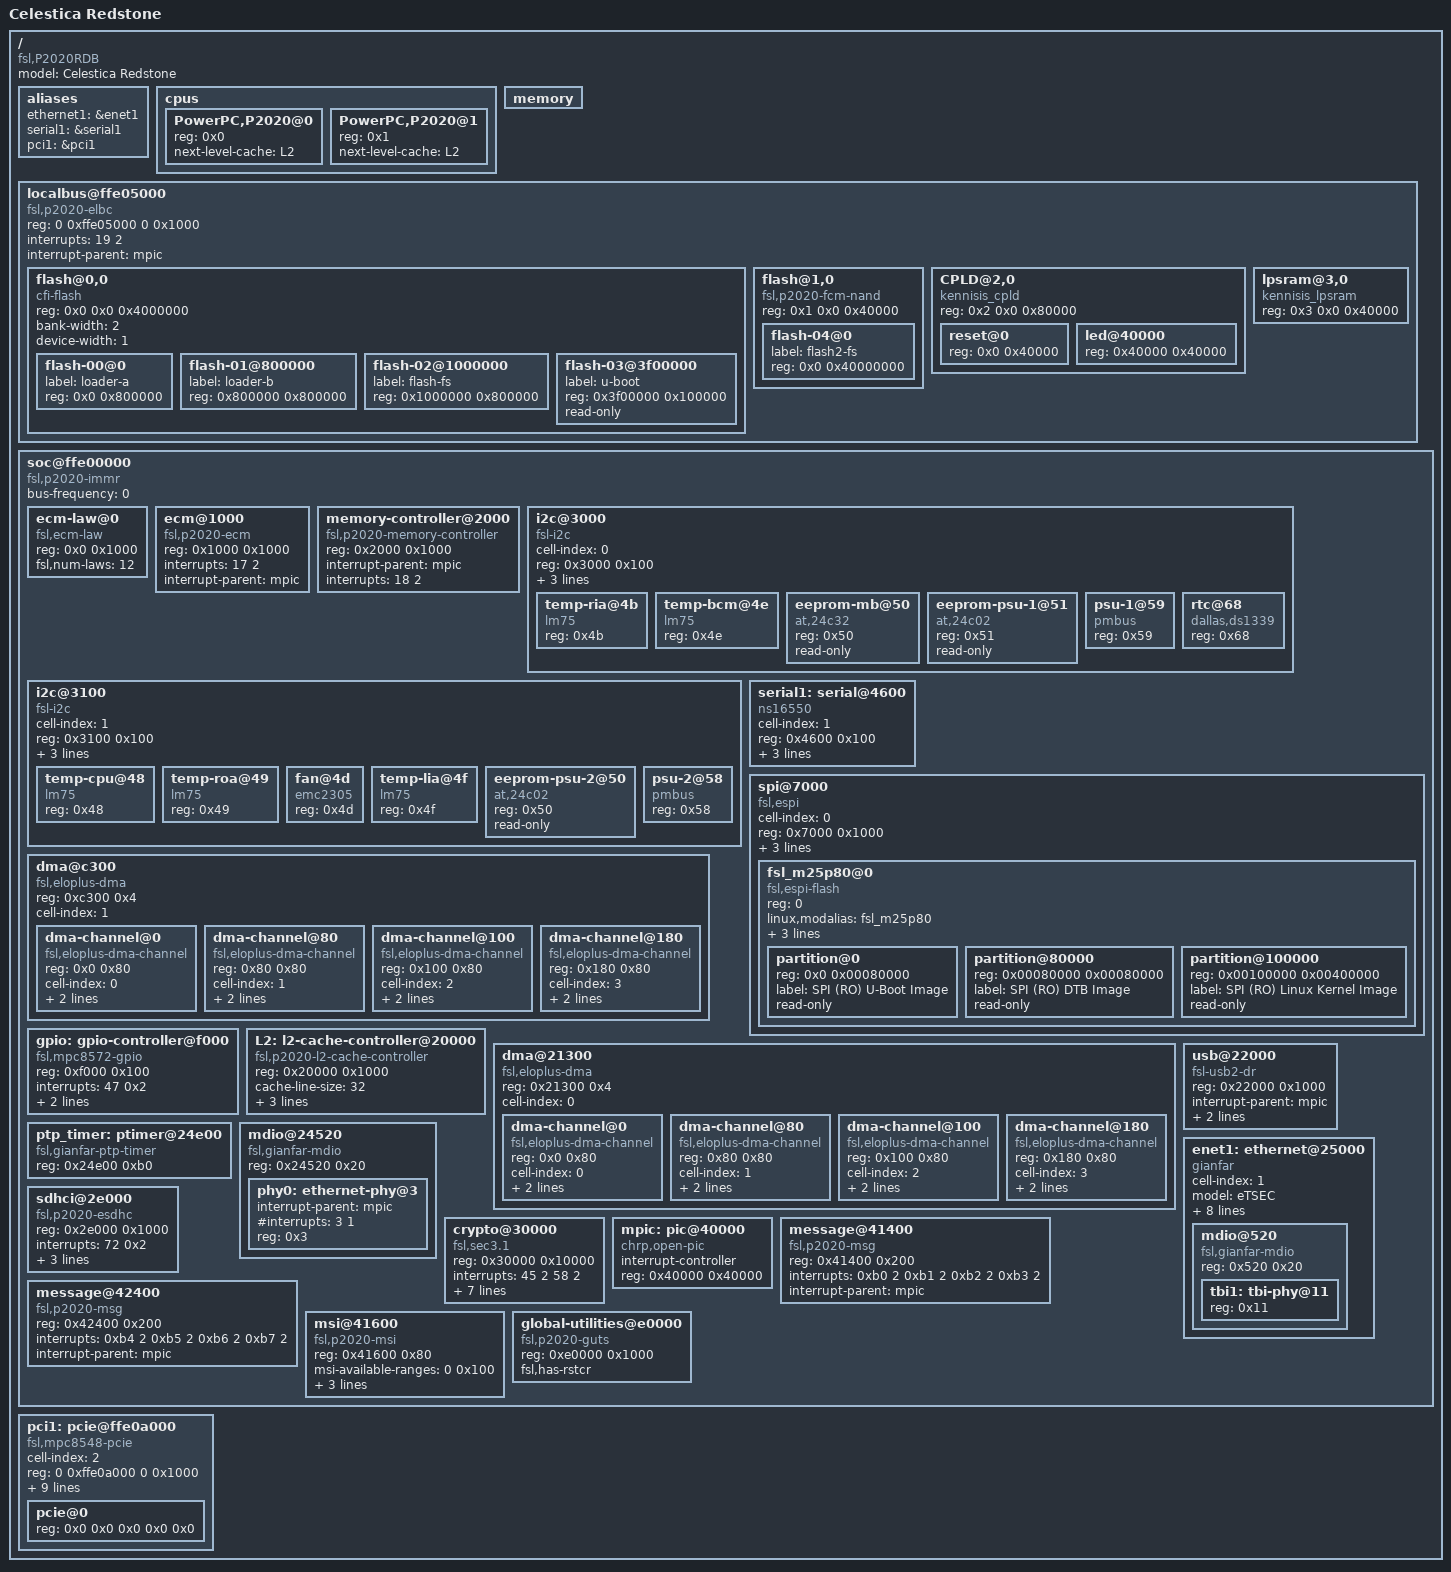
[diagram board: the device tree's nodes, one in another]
/*
 * Celestica Redstone device tree source
 *
 * Copyright 2013 Big Switch Networks, Inc.
 *
 * This program is free software; you can redistribute  it and/or modify it
 * under  the terms of  the GNU General  Public License as published by the
 * Free Software Foundation;  either version 2 of the  License, or (at your
 * option) any later version.
 */

/dts-v1/;

/ {
	model = "Celestica Redstone";
	compatible = "fsl,P2020RDB";
	#address-cells = <2>;
	#size-cells = <2>;

	aliases {
		ethernet1 = &enet1;
		serial1 = &serial1;
		pci1 = &pci1;
	};

	cpus {
		#address-cells = <1>;
		#size-cells = <0>;

		PowerPC,P2020@0 {
			device_type = "cpu";
			reg = <0x0>;
			next-level-cache = <&L2>;
		};

		PowerPC,P2020@1 {
			device_type = "cpu";
			reg = <0x1>;
			next-level-cache = <&L2>;
		};
	};

	memory {
		device_type = "memory";
	};

	localbus@ffe05000 {
		#address-cells = <2>;
		#size-cells = <1>;
		compatible = "fsl,p2020-elbc", "fsl,elbc", "simple-bus";
		reg = <0 0xffe05000 0 0x1000>;
		interrupts = <19 2>;
		interrupt-parent = <&mpic>;

		ranges = <0x0 0x0 0x0 0xec000000 0x4000000
			  0x1 0x0 0x0 0xffa00000 0x40000
			  0x2 0x0 0x0 0xffb00000 0x80000
			  0x3 0x0 0x0 0xffb80000 0x40000>;

		flash@0,0 {
			#address-cells = <1>;
			#size-cells = <1>;
			compatible = "cfi-flash";
			reg = <0x0 0x0 0x4000000>;
			bank-width = <2>;
			device-width = <1>;

			flash-00@0 {
				label = "loader-a";
				reg = <0x0 0x800000>;
			};

			flash-01@800000 {
				label = "loader-b";
				reg = <0x800000 0x800000>;
			};

			flash-02@1000000 {
				label = "flash-fs";
				reg = <0x1000000 0x800000>;
			};

			flash-03@3f00000 {
				label = "u-boot";
				reg = <0x3f00000 0x100000>;
				read-only;
			};
		};

		flash@1,0 {
			#address-cells = <1>;
			#size-cells = <1>;
			compatible = "fsl,p2020-fcm-nand",
				     "fsl,elbc-fcm-nand";
			reg = <0x1 0x0 0x40000>;

			flash-04@0 {
				label = "flash2-fs";
				reg = <0x0 0x40000000>;
			};
		};

		CPLD@2,0 {
			#address-cells = <1>;
			#size-cells = <1>;
			compatible = "kennisis_cpld";
			reg = <0x2 0x0 0x80000>;

			reset@0 {
				reg = <0x0 0x40000>;
			};
			led@40000 {
				reg = <0x40000 0x40000>;
			};
		};

		lpsram@3,0 {
			#address-cells = <1>;
			#size-cells = <1>;
			compatible = "kennisis_lpsram";
			reg = <0x3 0x0 0x40000>;
		};

	};

	soc@ffe00000 {
		#address-cells = <1>;
		#size-cells = <1>;
		device_type = "soc";
		compatible = "fsl,p2020-immr", "simple-bus";
		ranges = <0x0  0x0 0xffe00000 0x100000>;
		bus-frequency = <0>;		// Filled out by uboot.

		ecm-law@0 {
			compatible = "fsl,ecm-law";
			reg = <0x0 0x1000>;
			fsl,num-laws = <12>;
		};

		ecm@1000 {
			compatible = "fsl,p2020-ecm", "fsl,ecm";
			reg = <0x1000 0x1000>;
			interrupts = <17 2>;
			interrupt-parent = <&mpic>;
		};

		memory-controller@2000 {
			compatible = "fsl,p2020-memory-controller";
			reg = <0x2000 0x1000>;
			interrupt-parent = <&mpic>;
			interrupts = <18 2>;
		};

		i2c@3000 {
			#address-cells = <1>;
			#size-cells = <0>;
			cell-index = <0>;
			compatible = "fsl-i2c";
			reg = <0x3000 0x100>;
			interrupts = <43 2>;
			interrupt-parent = <&mpic>;
			dfsrr;

			temp-ria@4b {
				compatible = "lm75";
				reg = <0x4b>;
			};

			temp-bcm@4e {
				compatible = "lm75";
				reg = <0x4e>;
			};

			eeprom-mb@50 {
				compatible = "at,24c32";
				reg = <0x50>;
				read-only;
			};

			eeprom-psu-1@51 {
				compatible = "at,24c02";
				reg = <0x51>;
				read-only;
			};

			psu-1@59 {
				compatible = "pmbus";
				reg = <0x59>;
			};

			rtc@68 {
				compatible = "dallas,ds1339";
				reg = <0x68>;
			};

		};

		i2c@3100 {
			#address-cells = <1>;
			#size-cells = <0>;
			cell-index = <1>;
			compatible = "fsl-i2c";
			reg = <0x3100 0x100>;
			interrupts = <43 2>;
			interrupt-parent = <&mpic>;
			dfsrr;

			temp-cpu@48 {
				compatible = "lm75";
				reg = <0x48>;
			};

			temp-roa@49 {
				compatible = "lm75";
				reg = <0x49>;
			};

			fan@4d {
				compatible = "emc2305";
				reg = <0x4d>;
			};

			temp-lia@4f {
				compatible = "lm75";
				reg = <0x4f>;
			};

			eeprom-psu-2@50 {
				compatible = "at,24c02";
				reg = <0x50>;
				read-only;
			};

			psu-2@58 {
				compatible = "pmbus";
				reg = <0x58>;
			};
		};

		serial1: serial@4600 {
			cell-index = <1>;
			device_type = "serial";
			compatible = "ns16550";
			reg = <0x4600 0x100>;
			clock-frequency = <0>;
			interrupts = <42 2>;
			interrupt-parent = <&mpic>;
		};

		spi@7000 {
			cell-index = <0>;
			#address-cells = <1>;
			#size-cells = <0>;
			compatible = "fsl,espi";
			reg = <0x7000 0x1000>;
			interrupts = <59 0x2>;
			interrupt-parent = <&mpic>;
			mode = "cpu";

			fsl_m25p80@0 {
				#address-cells = <1>;
				#size-cells = <1>;
				compatible = "fsl,espi-flash";
				reg = <0>;
				linux,modalias = "fsl_m25p80";
				modal = "s25sl128b";
				spi-max-frequency = <32000000>;
				mode = <0>;

				partition@0 {
					/* 512KB for u-boot Bootloader Image */
					reg = <0x0 0x00080000>;
					label = "SPI (RO) U-Boot Image";
					read-only;
				};

				partition@80000 {
					/* 512KB for DTB Image */
					reg = <0x00080000 0x00080000>;
					label = "SPI (RO) DTB Image";
					read-only;
				};

				partition@100000 {
					/* 4MB for Linux Kernel Image */
					reg = <0x00100000 0x00400000>;
					label = "SPI (RO) Linux Kernel Image";
					read-only;
				};

			};
		};

		dma@c300 {
			#address-cells = <1>;
			#size-cells = <1>;
			compatible = "fsl,eloplus-dma";
			reg = <0xc300 0x4>;
			ranges = <0x0 0xc100 0x200>;
			cell-index = <1>;
			dma-channel@0 {
				compatible = "fsl,eloplus-dma-channel";
				reg = <0x0 0x80>;
				cell-index = <0>;
				interrupt-parent = <&mpic>;
				interrupts = <76 2>;
			};
			dma-channel@80 {
				compatible = "fsl,eloplus-dma-channel";
				reg = <0x80 0x80>;
				cell-index = <1>;
				interrupt-parent = <&mpic>;
				interrupts = <77 2>;
			};
			dma-channel@100 {
				compatible = "fsl,eloplus-dma-channel";
				reg = <0x100 0x80>;
				cell-index = <2>;
				interrupt-parent = <&mpic>;
				interrupts = <78 2>;
			};
			dma-channel@180 {
				compatible = "fsl,eloplus-dma-channel";
				reg = <0x180 0x80>;
				cell-index = <3>;
				interrupt-parent = <&mpic>;
				interrupts = <79 2>;
			};
		};

		gpio: gpio-controller@f000 {
			#gpio-cells = <2>;
			compatible = "fsl,mpc8572-gpio";
			reg = <0xf000 0x100>;
			interrupts = <47 0x2>;
			interrupt-parent = <&mpic>;
			gpio-controller;
		};

		L2: l2-cache-controller@20000 {
			compatible = "fsl,p2020-l2-cache-controller";
			reg = <0x20000 0x1000>;
			cache-line-size = <32>;	// 32 bytes
			cache-size = <0x80000>; // L2,512K
			interrupt-parent = <&mpic>;
			interrupts = <16 2>;
		};

		dma@21300 {
			#address-cells = <1>;
			#size-cells = <1>;
			compatible = "fsl,eloplus-dma";
			reg = <0x21300 0x4>;
			ranges = <0x0 0x21100 0x200>;
			cell-index = <0>;
			dma-channel@0 {
				compatible = "fsl,eloplus-dma-channel";
				reg = <0x0 0x80>;
				cell-index = <0>;
				interrupt-parent = <&mpic>;
				interrupts = <20 2>;
			};
			dma-channel@80 {
				compatible = "fsl,eloplus-dma-channel";
				reg = <0x80 0x80>;
				cell-index = <1>;
				interrupt-parent = <&mpic>;
				interrupts = <21 2>;
			};
			dma-channel@100 {
				compatible = "fsl,eloplus-dma-channel";
				reg = <0x100 0x80>;
				cell-index = <2>;
				interrupt-parent = <&mpic>;
				interrupts = <22 2>;
			};
			dma-channel@180 {
				compatible = "fsl,eloplus-dma-channel";
				reg = <0x180 0x80>;
				cell-index = <3>;
				interrupt-parent = <&mpic>;
				interrupts = <23 2>;
			};
		};

		usb@22000 {
			#address-cells = <1>;
			#size-cells = <0>;
			compatible = "fsl-usb2-dr";
			reg = <0x22000 0x1000>;
			interrupt-parent = <&mpic>;
			interrupts = <28 0x2>;
			phy_type = "ulpi";
		};

		ptp_timer: ptimer@24e00 {
			compatible = "fsl,gianfar-ptp-timer";
			reg = <0x24e00 0xb0>;
		};

		mdio@24520 {
			#address-cells = <1>;
			#size-cells = <0>;
			compatible = "fsl,gianfar-mdio";
			reg = <0x24520 0x20>;

			phy0: ethernet-phy@3 {
				interrupt-parent = <&mpic>;
		              	#interrupts = <3 1>;
				reg = <0x3>;
			};
		};

		enet1: ethernet@25000 {
			#address-cells = <1>;
			#size-cells = <1>;
			cell-index = <1>;
			device_type = "network";
			model = "eTSEC";
			compatible = "gianfar";
			reg = <0x25000 0x1000>;
			ranges = <0x0 0x25000 0x1000>;
			local-mac-address = [ 00 00 00 00 00 00 ];
			interrupts = <35 2 36 2 40 2>;
			interrupt-parent = <&mpic>;
			tbi-handle = <&tbi1>;
			phy-handle = <&phy0>;
			phy-connection-type = "sgmii";
			ptimer-handle = <&ptp_timer>;

			mdio@520 {
				#address-cells = <1>;
				#size-cells = <0>;
				compatible = "fsl,gianfar-mdio"; 
				reg = <0x520 0x20>;

				tbi1: tbi-phy@11 {
					reg = <0x11>;
					device_type = "tbi-phy";
				};
				
			};
		};

		sdhci@2e000 {
			compatible = "fsl,p2020-esdhc", "fsl,esdhc";
			reg = <0x2e000 0x1000>;
			interrupts = <72 0x2>;
			interrupt-parent = <&mpic>;
			fsl,sdhci-adjust-timeout;
			/* Filled in by U-Boot */
			clock-frequency = <0>;
		};

		crypto@30000 {
			compatible = "fsl,sec3.1", "fsl,sec3.0", "fsl,sec2.4",
				     "fsl,sec2.2", "fsl,sec2.1", "fsl,sec2.0";
			reg = <0x30000 0x10000>;
			interrupts = <45 2 58 2>;
			interrupt-parent = <&mpic>;
			fsl,num-channels = <4>;
			fsl,channel-fifo-len = <24>;
			fsl,exec-units-mask = <0xbfe>;
			fsl,descriptor-types-mask = <0x3ab0ebf>;
			fsl,multi-host-mode = "dual";
			fsl,channel-remap = <0x3>;
		};

		mpic: pic@40000 {
			interrupt-controller;
			#address-cells = <0>;
			#interrupt-cells = <2>;
			reg = <0x40000 0x40000>;
			compatible = "chrp,open-pic";
			device_type = "open-pic";
		};

		message@41400 {
			compatible = "fsl,p2020-msg", "fsl,mpic-msg";
			reg = <0x41400 0x200>;
			interrupts = <
				0xb0 2
				0xb1 2
				0xb2 2
				0xb3 2>;
			interrupt-parent = <&mpic>;
		};

		message@42400 {
			compatible = "fsl,p2020-msg", "fsl,mpic-msg";
			reg = <0x42400 0x200>;
			interrupts = <
				0xb4 2
				0xb5 2
				0xb6 2
				0xb7 2>;
			interrupt-parent = <&mpic>;
		};

		msi@41600 {
			compatible = "fsl,p2020-msi", "fsl,mpic-msi";
			reg = <0x41600 0x80>;
			msi-available-ranges = <0 0x100>;
			interrupts = <
				0xe0 0
				0xe1 0
				0xe2 0
				0xe3 0
				0xe4 0
				0xe5 0
				0xe6 0
				0xe7 0>;
			interrupt-parent = <&mpic>;
		};

		global-utilities@e0000 {	//global utilities block
			compatible = "fsl,p2020-guts";
			reg = <0xe0000 0x1000>;
			fsl,has-rstcr;
		};
	};

	pci1: pcie@ffe0a000 {
		cell-index = <2>;
		compatible = "fsl,mpc8548-pcie";
		device_type = "pci";
		#interrupt-cells = <1>;
		#size-cells = <2>;
		#address-cells = <3>;
		reg = <0 0xffe0a000 0 0x1000>;
		bus-range = <0 255>;
		ranges = <0x2000000 0x0 0xc0000000 0 0xc0000000 0x0 0x20000000
			  0x1000000 0x0 0x00000000 0 0xffc30000 0x0 0x10000>;
		clock-frequency = <33333333>;
		interrupt-parent = <&mpic>;
		interrupts = <26 2>;
		interrupt-map-mask = <0xf800 0x0 0x0 0x7>;
		interrupt-map = <
			/* IDSEL 0x0 */
			0000 0x0 0x0 0x1 &mpic 0x0 0x1
			0000 0x0 0x0 0x2 &mpic 0x1 0x1
			0000 0x0 0x0 0x3 &mpic 0x2 0x1
			0000 0x0 0x0 0x4 &mpic 0x3 0x1
			>;
		pcie@0 {
			reg = <0x0 0x0 0x0 0x0 0x0>;
			#size-cells = <2>;
			#address-cells = <3>;
			device_type = "pci";
			ranges = <0x2000000 0x0 0xc0000000
				  0x2000000 0x0 0xc0000000
				  0x0 0x20000000

				  0x1000000 0x0 0x0
				  0x1000000 0x0 0x0
				  0x0 0x100000>;
		};
	};
};
